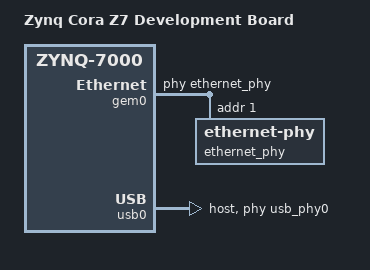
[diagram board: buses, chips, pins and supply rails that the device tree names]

#include "system-top.dts"

/ {
	model = "Zynq Cora Z7 Development Board";
	compatible = "digilent,zynq-coraz7", "xlnx,zynq-7000";

	chosen {
		bootargs = "console=ttyPS0,115200 root=/dev/mmcblk0p2 rw rootwait earlyprintk uio_pdrv_genirq.of_id=generic-uio";
	};

	usb_phy0: phy0@e0002000 {
		compatible = "ulpi-phy";
		#phy-cells = <0>;
		reg = <0xe0002000 0x1000>;
		view-port = <0x0170>;
		drv-vbus;
	};
};

&gem0 {
	/* MAC address of board is available on sticker */
	local-mac-address = [00 18 3e 03 66 3f];
	phy-handle = <&ethernet_phy>;
	ethernet_phy: ethernet-phy@1 { /* rtl8211e-vl */
		reg = <1>;
		device_type = "ethernet-phy";
	};
};

&usb0 {	
	dr_mode = "host";
	usb-phy = <&usb_phy0>;
};

&sdhci0 {
	u-boot,dm-pre-reloc;
};

&uart0 {
	u-boot,dm-pre-reloc;
};
